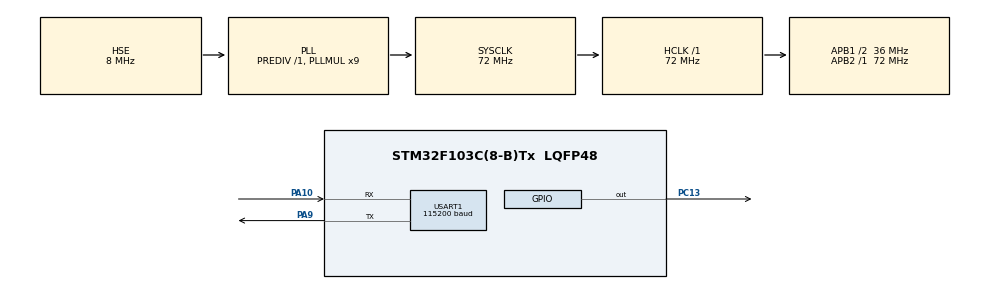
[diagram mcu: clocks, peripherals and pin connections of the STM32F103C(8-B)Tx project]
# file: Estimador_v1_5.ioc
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Mcu.Family=STM32F1
RCC.PLLSourceVirtual=RCC_PLLSOURCE_HSE
PD1-OSC_OUT.Mode=HSE-External-Oscillator
PA10.Mode=Asynchronous
USART1.BaudRate=115200
PC13-TAMPER-RTC.Signal=GPIO_Output
RCC.USBPrescaler=RCC_USBCLKSOURCE_PLL_DIV1_5
PD0-OSC_IN.Signal=RCC_OSC_IN
RCC.APB1CLKDivider=RCC_HCLK_DIV2
RCC.SYSCLKSource=RCC_SYSCLKSOURCE_PLLCLK
ProjectManager.StackSize=0x400
PD1-OSC_OUT.Signal=RCC_OSC_OUT
RCC.ADCPresc=RCC_ADCPCLK2_DIV6
PA13.Signal=SYS_JTMS-SWDIO
PA9.Mode=Asynchronous
ProjectManager.TargetToolchain=STM32CubeIDE
RCC.HCLKFreq_Value=72000000
RCC.APB2TimFreq_Value=72000000
PA9.Signal=USART1_TX
RCC.USBFreq_Value=48000000
RCC.AHBFreq_Value=72000000
PD0-OSC_IN.Mode=HSE-External-Oscillator
board=custom
RCC.PLLMUL=RCC_PLL_MUL9
RCC.APB2Freq_Value=72000000
PA14.Mode=Serial_Wire
PA13.Mode=Serial_Wire
Mcu.Name=STM32F103C(8-B)Tx
RCC.SYSCLKFreq_VALUE=72000000
Mcu.Package=LQFP48
USART1.VirtualMode=VM_ASYNC
PA10.Signal=USART1_RX
PA14.Signal=SYS_JTCK-SWCLK
ProjectManager.HeapSize=0x200
NVIC.PriorityGroup=NVIC_PRIORITYGROUP_4
RCC.APB1TimFreq_Value=72000000
NVIC.USART1_IRQn=true\:0\:0\:false\:false\:true\:true\:true
RCC.APB1Freq_Value=36000000

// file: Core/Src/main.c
/* USER CODE BEGIN Header */
/**
  ******************************************************************************
  * @file           : main.c
  * @brief          : Main program body
  ******************************************************************************
  * @attention
  *
  * <h2><center>&copy; Copyright (c) 2021 STMicroelectronics.
  * All rights reserved.</center></h2>
  *
  * This software component is licensed by ST under Ultimate Liberty license
  * SLA0044, the "License"; You may not use this file except in compliance with
  * the License. You may obtain a copy of the License at:
  *                             www.st.com/SLA0044
  *
  ******************************************************************************
  */
/* USER CODE END Header */
#include "main.h"

/* USER CODE BEGIN Includes */
#include "muestras_corriente.h"
#include "fdacoefs.h"
#include "fda_derivador.h"
#include <stdio.h>
#include <stdlib.h>
#include <math.h>
#include <string.h>
/* USER CODE END Includes */

/* USER CODE BEGIN PTD */
#define min(a,b) (((a)<(b))?(a):(b))
#define max(a,b) (((a)>(b))?(a):(b))
/* USER CODE END PTD */

UART_HandleTypeDef huart1;

void SystemClock_Config(void);
static void MX_GPIO_Init(void);
static void MX_USART1_UART_Init(void);

/* USER CODE BEGIN 0 */

uint8_t printSerial = 1;

#define numSamples  50
const uint16_t fs = 50000;
const float alfa = 0.4665119;			//el alfa sale de alfa = 1 - exp(-2pi*fc/fs) fc es la frecuencia de corte
const float RL = 0.2;
const float L_4mm = 16.2e-3;
const float Kh = 0.05;				//transductancia del sensor de efecto Hall
uint16_t vilIndex = 0;
#define N_ADC 16
const int n = N_ADC - 1;
float muestrasADC[N_ADC];
float IL[N_ADC];
float ILmed;
float deltaIL;
float derivadas[N_ADC];
float derivadas_filtrada[N_ADC];
float Yestimada[N_ADC];
float Yestimada_1[N_ADC];
float Yestimada_filtrada[N_ADC];

float corriente(float Xn){
		return Xn / Kh;
}

float corriente_media(float * IL){
	float sum = 0;
	for(int i = 0; i<numSamples; i++){
		sum += IL[i];
	}
	return sum/numSamples;
}

float delta_corriente(float  IL){
	static float ILmax = 0;
	static float ILmin = 100;
	ILmax = max(IL, ILmax);
	ILmin = min(IL, ILmin);
	return ILmax - ILmin;
}

float derivar(float * muestrasADC, float ILmed){
	float deriv = 	(muestrasADC[n] - muestrasADC[n - 1]) * fs;
	deriv += ILmed * 0.05 * RL / L_4mm;			//corrección I * R
	return deriv;
}

float estimar(float derivada){
		float estim = (20 * abs(derivada) - 7.75e2) / 1.7e5;
		if(estim < 8e-3)
			return estim;
		else
			return 8e-3;						//esto lo hago para que la primera muestra no sea tan erronea
}

float filtrar(float * X, const float * B){			//acá la Y significa la salida del filtro, no la posición en mm
	float out = 0;
	for (int i = 0; i < N_ADC; i++) {				//acá aplico el filtro
		out += B[i] * X[n - i];			//B son los coeficientes de un filtro FIR
	 }
	 return out;
}

float promediar(float * Yestimada){
	float sum = 0;
	for(int i = 0; i < numSamples; i++){
		sum += Yestimada[i];
	}
	return sum / numSamples;
}

/* USER CODE END 0 */

int main(void)
{

  /* MCU Configuration--------------------------------------------------------*/

  /* Reset of all peripherals, Initializes the Flash interface and the Systick. */
  HAL_Init();

  /* Configure the system clock */
  SystemClock_Config();

  /* Initialize all configured peripherals */
  MX_GPIO_Init();
  MX_USART1_UART_Init();

  /* Infinite loop */
  while (1)
  {

    /* USER CODE BEGIN 3 */

	  //leo la muestra de corriente y la pongo al final del array del ADC
	  muestrasADC[n] = ViL[vilIndex];
	  IL[n] = corriente(muestrasADC[n]);			//calculo el valor en corriente
	  ILmed = alfa * IL[n] + (1 - alfa) * ILmed;		//exponential integrator
	  //  ILmed = (IL[n] + ILmed) / 2;							//añado al promedio movil
	  //deltaIL
	  derivadas[n]  = abs(derivar(muestrasADC, IL[n]));		//acá calculo derivada y hago el valor absoluto
	  derivadas_filtrada[n] = filtrar(derivadas, Bderiv);	//filtro las derivadas obtenidas
	  Yestimada_1[n] = estimar(derivadas[n]);				//esto es para comparar con la filtrada
	  Yestimada[n]  = estimar(derivadas_filtrada[n]);		//estimacion
	  Yestimada_filtrada[n] = filtrar(Yestimada, Bposicion);	//filtro

	  //acá paso todos los valores un lugar a la izquierda
	  for (int i = n; i > 0; i--) {
	 		muestrasADC[n - i] = muestrasADC[n - i + 1];
	 		IL[n - i] = IL[n - i + 1];
	 		derivadas[n - i] = derivadas[n - i + 1];
	 		derivadas_filtrada[n - i] = derivadas_filtrada[n - i + 1];
	 		Yestimada[n - i] = Yestimada[n - i + 1];
	 		Yestimada_1[n - i] = Yestimada_1[n - i + 1];
	 		Yestimada_filtrada[n - i] = Yestimada_filtrada[n - i + 1];
	 	  }

	  //incremento el index y vuelvo a empezar a recorrer el arreglo de ViL si es necesario
	  vilIndex++;
	  if(vilIndex == 74)
		  vilIndex = 0;

	  if(printSerial){
		// uint16_t s1 = Yestimada[n] * 1e6;
		// uint16_t s2 = Yestimada_filtrada[n] * 1e6;
		  int16_t s1 = derivadas[n];
		  int16_t s2 = abs(derivadas[n]);
		 // int16_t s2 = derivadas_filtrada[n];
		 // uint16_t s1 = IL[n] * 1e3;
		 // uint16_t s2 = ILmed * 1e3;
		  char str[20];
		  sprintf(str, "%d,%d\r\n", s1, s2);
		 //sprintf(str, "%d\r\n,", s1);
		  HAL_UART_Transmit(&huart1, (uint8_t * ) str, strlen(str), 100);
	  }

	  HAL_Delay(30);
  }
  /* USER CODE END 3 */
}

void SystemClock_Config(void)
{
  RCC_OscInitTypeDef RCC_OscInitStruct = {0};
  RCC_ClkInitTypeDef RCC_ClkInitStruct = {0};

  /** Initializes the RCC Oscillators according to the specified parameters
  * in the RCC_OscInitTypeDef structure.
  */
  RCC_OscInitStruct.OscillatorType = RCC_OSCILLATORTYPE_HSE;
  RCC_OscInitStruct.HSEState = RCC_HSE_ON;
  RCC_OscInitStruct.HSEPredivValue = RCC_HSE_PREDIV_DIV1;
  RCC_OscInitStruct.HSIState = RCC_HSI_ON;
  RCC_OscInitStruct.PLL.PLLState = RCC_PLL_ON;
  RCC_OscInitStruct.PLL.PLLSource = RCC_PLLSOURCE_HSE;
  RCC_OscInitStruct.PLL.PLLMUL = RCC_PLL_MUL9;
  if (HAL_RCC_OscConfig(&RCC_OscInitStruct) != HAL_OK)
  {
    Error_Handler();
  }
  /** Initializes the CPU, AHB and APB buses clocks
  */
  RCC_ClkInitStruct.ClockType = RCC_CLOCKTYPE_HCLK|RCC_CLOCKTYPE_SYSCLK
                              |RCC_CLOCKTYPE_PCLK1|RCC_CLOCKTYPE_PCLK2;
  RCC_ClkInitStruct.SYSCLKSource = RCC_SYSCLKSOURCE_PLLCLK;
  RCC_ClkInitStruct.AHBCLKDivider = RCC_SYSCLK_DIV1;
  RCC_ClkInitStruct.APB1CLKDivider = RCC_HCLK_DIV2;
  RCC_ClkInitStruct.APB2CLKDivider = RCC_HCLK_DIV1;

  if (HAL_RCC_ClockConfig(&RCC_ClkInitStruct, FLASH_LATENCY_2) != HAL_OK)
  {
    Error_Handler();
  }
}

static void MX_USART1_UART_Init(void)
{

  huart1.Instance = USART1;
  huart1.Init.BaudRate = 115200;
  huart1.Init.WordLength = UART_WORDLENGTH_8B;
  huart1.Init.StopBits = UART_STOPBITS_1;
  huart1.Init.Parity = UART_PARITY_NONE;
  huart1.Init.Mode = UART_MODE_TX_RX;
  huart1.Init.HwFlowCtl = UART_HWCONTROL_NONE;
  huart1.Init.OverSampling = UART_OVERSAMPLING_16;
  if (HAL_UART_Init(&huart1) != HAL_OK)
  {
    Error_Handler();
  }

}

static void MX_GPIO_Init(void)
{
  GPIO_InitTypeDef GPIO_InitStruct = {0};

  /* GPIO Ports Clock Enable */
  __HAL_RCC_GPIOC_CLK_ENABLE();
  __HAL_RCC_GPIOD_CLK_ENABLE();
  __HAL_RCC_GPIOA_CLK_ENABLE();

  /*Configure GPIO pin Output Level */
  HAL_GPIO_WritePin(GPIOC, GPIO_PIN_13, GPIO_PIN_RESET);

  /*Configure GPIO pin : PC13 */
  GPIO_InitStruct.Pin = GPIO_PIN_13;
  GPIO_InitStruct.Mode = GPIO_MODE_OUTPUT_PP;
  GPIO_InitStruct.Pull = GPIO_NOPULL;
  GPIO_InitStruct.Speed = GPIO_SPEED_FREQ_LOW;
  HAL_GPIO_Init(GPIOC, &GPIO_InitStruct);

}

void Error_Handler(void)
{
  __disable_irq();
  while (1)
  {
  }
}

/************************ (C) COPYRIGHT STMicroelectronics *****END OF FILE****/
